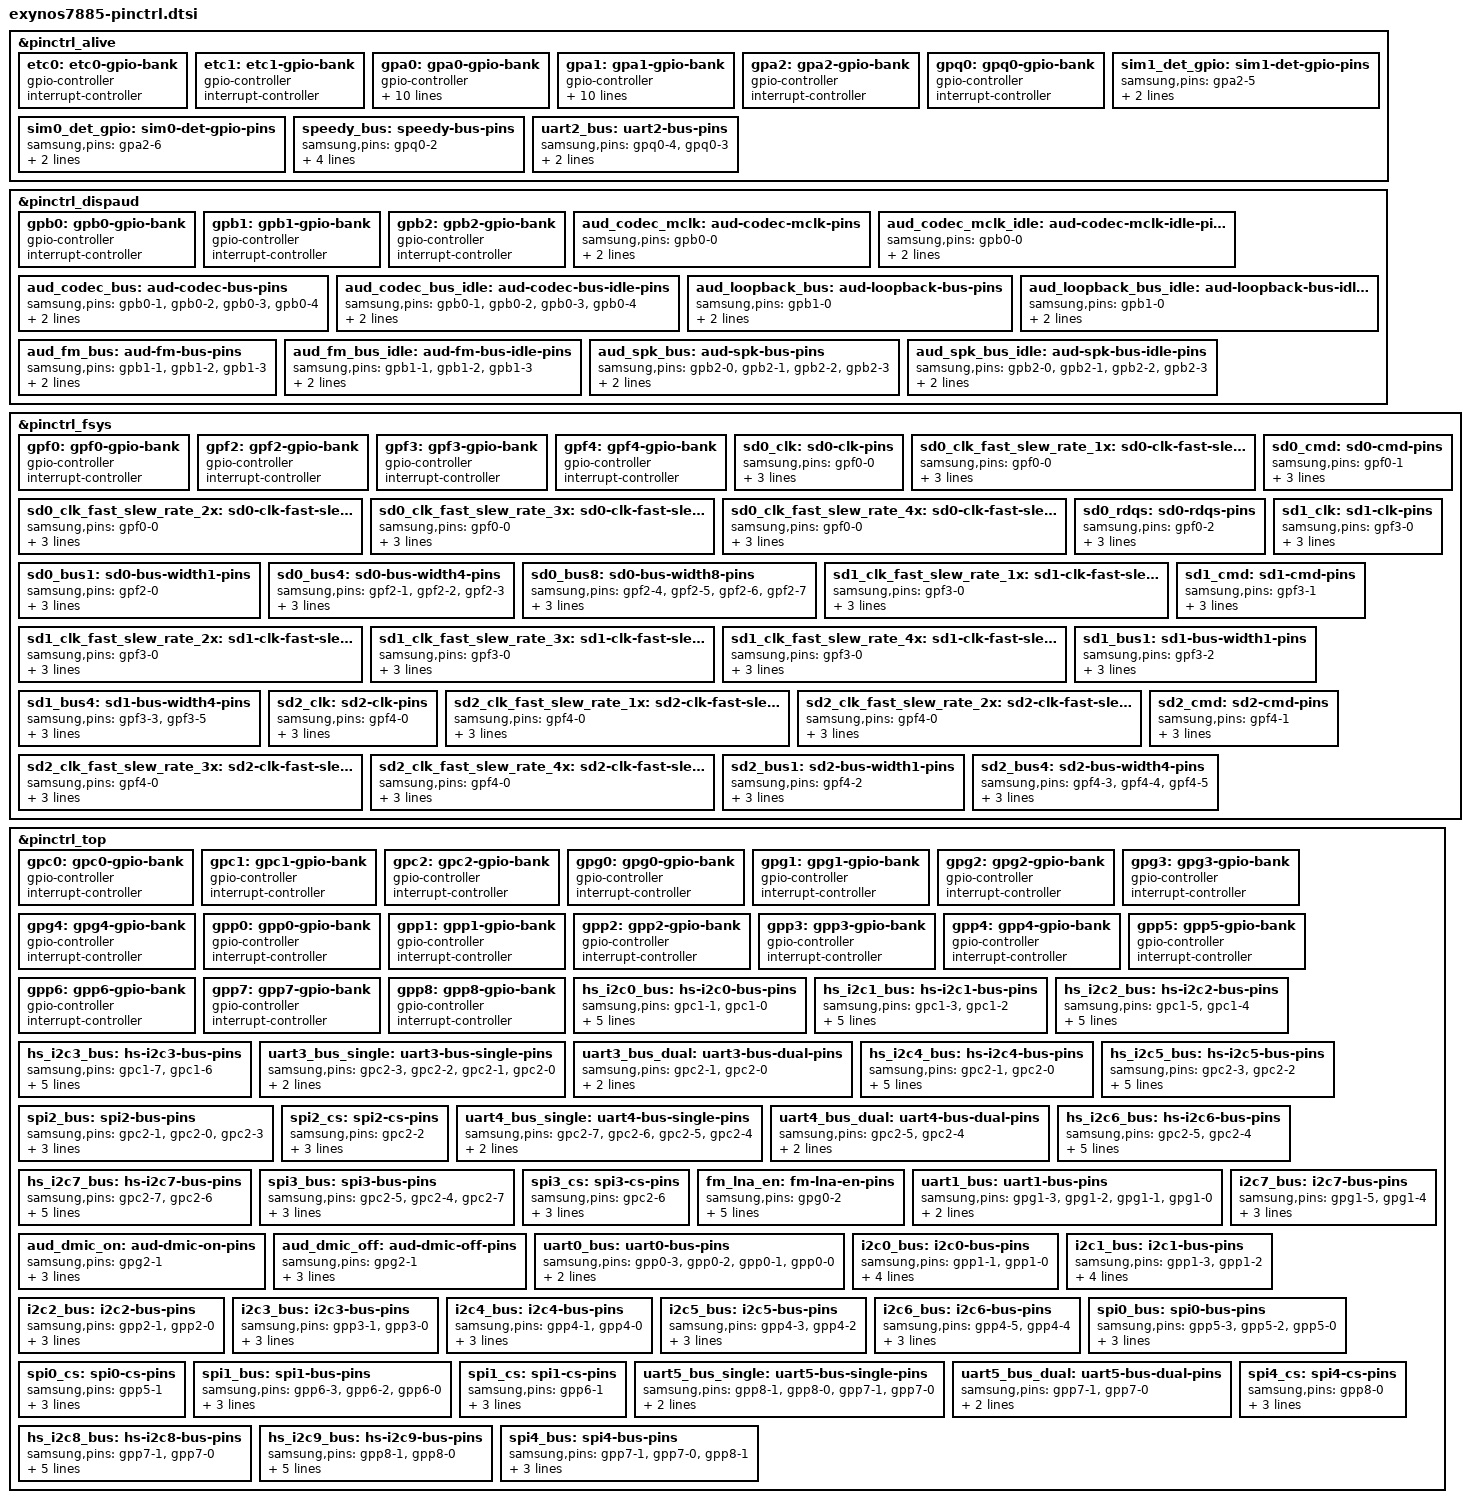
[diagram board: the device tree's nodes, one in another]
// SPDX-License-Identifier: GPL-2.0
/*
 * Samsung Exynos7885 SoC pin-mux and pin-config device tree source
 *
 * Copyright (c) 2017 Samsung Electronics Co., Ltd.
 * Copyright (c) 2021 Dávid Virág
 *
 * Samsung's Exynos7885 SoC pin-mux and pin-config options are listed as
 * device tree nodes in this file.
 */

#include <dt-bindings/pinctrl/samsung.h>
#include <dt-bindings/interrupt-controller/arm-gic.h>

&pinctrl_alive {
	etc0: etc0-gpio-bank {
		gpio-controller;
		#gpio-cells = <2>;

		interrupt-controller;
		#interrupt-cells = <2>;
	};

	etc1: etc1-gpio-bank {
		gpio-controller;
		#gpio-cells = <2>;

		interrupt-controller;
		#interrupt-cells = <2>;
	};

	gpa0: gpa0-gpio-bank {
		gpio-controller;
		#gpio-cells = <2>;

		interrupt-controller;
		#interrupt-cells = <2>;
		interrupt-parent = <&gic>;
		interrupts = <GIC_SPI 0 IRQ_TYPE_LEVEL_HIGH>,
			     <GIC_SPI 1 IRQ_TYPE_LEVEL_HIGH>,
			     <GIC_SPI 2 IRQ_TYPE_LEVEL_HIGH>,
			     <GIC_SPI 3 IRQ_TYPE_LEVEL_HIGH>,
			     <GIC_SPI 4 IRQ_TYPE_LEVEL_HIGH>,
			     <GIC_SPI 5 IRQ_TYPE_LEVEL_HIGH>,
			     <GIC_SPI 6 IRQ_TYPE_LEVEL_HIGH>,
			     <GIC_SPI 7 IRQ_TYPE_LEVEL_HIGH>;
	};

	gpa1: gpa1-gpio-bank {
		gpio-controller;
		#gpio-cells = <2>;

		interrupt-controller;
		#interrupt-cells = <2>;
		interrupt-parent = <&gic>;
		interrupts = <GIC_SPI 8 IRQ_TYPE_LEVEL_HIGH>,
			     <GIC_SPI 9 IRQ_TYPE_LEVEL_HIGH>,
			     <GIC_SPI 10 IRQ_TYPE_LEVEL_HIGH>,
			     <GIC_SPI 11 IRQ_TYPE_LEVEL_HIGH>,
			     <GIC_SPI 12 IRQ_TYPE_LEVEL_HIGH>,
			     <GIC_SPI 13 IRQ_TYPE_LEVEL_HIGH>,
			     <GIC_SPI 14 IRQ_TYPE_LEVEL_HIGH>,
			     <GIC_SPI 15 IRQ_TYPE_LEVEL_HIGH>;
	};

	gpa2: gpa2-gpio-bank {
		gpio-controller;
		#gpio-cells = <2>;

		interrupt-controller;
		#interrupt-cells = <2>;
	};

	gpq0: gpq0-gpio-bank {
		gpio-controller;
		#gpio-cells = <2>;

		interrupt-controller;
		#interrupt-cells = <2>;
	};

	sim1_det_gpio: sim1-det-gpio-pins {
		samsung,pins = "gpa2-5";
		samsung,pin-function = <EXYNOS_PIN_FUNC_F>;
		samsung,pin-pud = <EXYNOS_PIN_PULL_NONE>;
	};

	sim0_det_gpio: sim0-det-gpio-pins {
		samsung,pins = "gpa2-6";
		samsung,pin-function = <EXYNOS_PIN_FUNC_F>;
		samsung,pin-pud = <EXYNOS_PIN_PULL_NONE>;
	};

	speedy_bus: speedy-bus-pins {
		samsung,pins = "gpq0-2";
		samsung,pin-function = <EXYNOS_PIN_FUNC_2>;
		samsung,pin-con-pdn = <EXYNOS_PIN_PDN_PREV>;
		samsung,pin-pud = <EXYNOS_PIN_PULL_UP>;
		samsung,pin-drv = <EXYNOS5420_PIN_DRV_LV1>;
	};

	/* UART_DEBUG */
	uart2_bus: uart2-bus-pins {
		samsung,pins = "gpq0-4", "gpq0-3";
		samsung,pin-function = <EXYNOS_PIN_FUNC_2>;
		samsung,pin-pud = <EXYNOS_PIN_PULL_NONE>;
	};
};

&pinctrl_dispaud {
	gpb0: gpb0-gpio-bank {
		gpio-controller;
		#gpio-cells = <2>;

		interrupt-controller;
		#interrupt-cells = <2>;
	};

	gpb1: gpb1-gpio-bank {
		gpio-controller;
		#gpio-cells = <2>;

		interrupt-controller;
		#interrupt-cells = <2>;
	};

	gpb2: gpb2-gpio-bank {
		gpio-controller;
		#gpio-cells = <2>;

		interrupt-controller;
		#interrupt-cells = <2>;
	};

	aud_codec_mclk: aud-codec-mclk-pins {
		samsung,pins = "gpb0-0";
		samsung,pin-function = <EXYNOS_PIN_FUNC_2>;
		samsung,pin-pud = <EXYNOS_PIN_PULL_DOWN>;
	};

	aud_codec_mclk_idle: aud-codec-mclk-idle-pins {
		samsung,pins = "gpb0-0";
		samsung,pin-function = <EXYNOS_PIN_FUNC_INPUT>;
		samsung,pin-pud = <EXYNOS_PIN_PULL_DOWN>;
	};

	aud_codec_bus: aud-codec-bus-pins {
		samsung,pins = "gpb0-1", "gpb0-2", "gpb0-3", "gpb0-4";
		samsung,pin-function = <EXYNOS_PIN_FUNC_2>;
		samsung,pin-pud = <EXYNOS_PIN_PULL_DOWN>;
	};

	aud_codec_bus_idle: aud-codec-bus-idle-pins {
		samsung,pins = "gpb0-1", "gpb0-2", "gpb0-3", "gpb0-4";
		samsung,pin-function = <EXYNOS_PIN_FUNC_INPUT>;
		samsung,pin-pud = <EXYNOS_PIN_PULL_DOWN>;
	};

	aud_loopback_bus: aud-loopback-bus-pins {
		samsung,pins = "gpb1-0";
		samsung,pin-function = <EXYNOS_PIN_FUNC_2>;
		samsung,pin-pud = <EXYNOS_PIN_PULL_DOWN>;
	};

	aud_loopback_bus_idle: aud-loopback-bus-idle-pins {
		samsung,pins = "gpb1-0";
		samsung,pin-function = <EXYNOS_PIN_FUNC_INPUT>;
		samsung,pin-pud = <EXYNOS_PIN_PULL_DOWN>;
	};

	aud_fm_bus: aud-fm-bus-pins {
		samsung,pins = "gpb1-1", "gpb1-2", "gpb1-3";
		samsung,pin-function = <EXYNOS_PIN_FUNC_2>;
		samsung,pin-pud = <EXYNOS_PIN_PULL_DOWN>;
	};

	aud_fm_bus_idle: aud-fm-bus-idle-pins {
		samsung,pins = "gpb1-1", "gpb1-2", "gpb1-3";
		samsung,pin-function = <EXYNOS_PIN_FUNC_INPUT>;
		samsung,pin-pud = <EXYNOS_PIN_PULL_DOWN>;
	};

	aud_spk_bus: aud-spk-bus-pins {
		samsung,pins = "gpb2-0", "gpb2-1", "gpb2-2", "gpb2-3";
		samsung,pin-function = <EXYNOS_PIN_FUNC_2>;
		samsung,pin-pud = <EXYNOS_PIN_PULL_DOWN>;
	};

	aud_spk_bus_idle: aud-spk-bus-idle-pins {
		samsung,pins = "gpb2-0", "gpb2-1", "gpb2-2", "gpb2-3";
		samsung,pin-function = <EXYNOS_PIN_FUNC_INPUT>;
		samsung,pin-pud = <EXYNOS_PIN_PULL_DOWN>;
	};
};

&pinctrl_fsys {
	gpf0: gpf0-gpio-bank {
		gpio-controller;
		#gpio-cells = <2>;

		interrupt-controller;
		#interrupt-cells = <2>;
	};

	gpf2: gpf2-gpio-bank {
		gpio-controller;
		#gpio-cells = <2>;

		interrupt-controller;
		#interrupt-cells = <2>;
	};

	gpf3: gpf3-gpio-bank {
		gpio-controller;
		#gpio-cells = <2>;

		interrupt-controller;
		#interrupt-cells = <2>;
	};

	gpf4: gpf4-gpio-bank {
		gpio-controller;
		#gpio-cells = <2>;

		interrupt-controller;
		#interrupt-cells = <2>;
	};

	sd0_clk: sd0-clk-pins {
		samsung,pins = "gpf0-0";
		samsung,pin-function = <EXYNOS_PIN_FUNC_2>;
		samsung,pin-pud = <EXYNOS_PIN_PULL_NONE>;
		samsung,pin-drv = <EXYNOS5420_PIN_DRV_LV4>;
	};

	sd0_clk_fast_slew_rate_1x: sd0-clk-fast-slew-rate-1x-pins {
		samsung,pins = "gpf0-0";
		samsung,pin-function = <EXYNOS_PIN_FUNC_2>;
		samsung,pin-pud = <EXYNOS_PIN_PULL_NONE>;
		samsung,pin-drv = <EXYNOS5420_PIN_DRV_LV1>;
	};

	sd0_clk_fast_slew_rate_2x: sd0-clk-fast-slew-rate-2x-pins {
		samsung,pins = "gpf0-0";
		samsung,pin-function = <EXYNOS_PIN_FUNC_2>;
		samsung,pin-pud = <EXYNOS_PIN_PULL_NONE>;
		samsung,pin-drv = <EXYNOS5420_PIN_DRV_LV2>;
	};

	sd0_clk_fast_slew_rate_3x: sd0-clk-fast-slew-rate-3x-pins {
		samsung,pins = "gpf0-0";
		samsung,pin-function = <EXYNOS_PIN_FUNC_2>;
		samsung,pin-pud = <EXYNOS_PIN_PULL_NONE>;
		samsung,pin-drv = <EXYNOS5420_PIN_DRV_LV3>;
	};

	sd0_clk_fast_slew_rate_4x: sd0-clk-fast-slew-rate-4x-pins {
		samsung,pins = "gpf0-0";
		samsung,pin-function = <EXYNOS_PIN_FUNC_2>;
		samsung,pin-pud = <EXYNOS_PIN_PULL_NONE>;
		samsung,pin-drv = <EXYNOS5420_PIN_DRV_LV4>;
	};

	sd0_cmd: sd0-cmd-pins {
		samsung,pins = "gpf0-1";
		samsung,pin-function = <EXYNOS_PIN_FUNC_2>;
		samsung,pin-pud = <EXYNOS_PIN_PULL_UP>;
		samsung,pin-drv = <EXYNOS5420_PIN_DRV_LV4>;
	};

	sd0_rdqs: sd0-rdqs-pins {
		samsung,pins = "gpf0-2";
		samsung,pin-function = <EXYNOS_PIN_FUNC_2>;
		samsung,pin-pud = <EXYNOS_PIN_PULL_DOWN>;
		samsung,pin-drv = <EXYNOS5420_PIN_DRV_LV4>;
	};

	sd0_bus1: sd0-bus-width1-pins {
		samsung,pins = "gpf2-0";
		samsung,pin-function = <EXYNOS_PIN_FUNC_2>;
		samsung,pin-pud = <EXYNOS_PIN_PULL_UP>;
		samsung,pin-drv = <EXYNOS5420_PIN_DRV_LV4>;
	};

	sd0_bus4: sd0-bus-width4-pins {
		samsung,pins = "gpf2-1", "gpf2-2", "gpf2-3";
		samsung,pin-function = <EXYNOS_PIN_FUNC_2>;
		samsung,pin-pud = <EXYNOS_PIN_PULL_UP>;
		samsung,pin-drv = <EXYNOS5420_PIN_DRV_LV4>;
	};

	sd0_bus8: sd0-bus-width8-pins {
		samsung,pins = "gpf2-4", "gpf2-5", "gpf2-6", "gpf2-7";
		samsung,pin-function = <EXYNOS_PIN_FUNC_2>;
		samsung,pin-pud = <EXYNOS_PIN_PULL_UP>;
		samsung,pin-drv = <EXYNOS5420_PIN_DRV_LV4>;
	};

	sd1_clk: sd1-clk-pins {
		samsung,pins = "gpf3-0";
		samsung,pin-function = <EXYNOS_PIN_FUNC_2>;
		samsung,pin-pud = <EXYNOS_PIN_PULL_NONE>;
		samsung,pin-drv = <EXYNOS5420_PIN_DRV_LV3>;
	};

	sd1_clk_fast_slew_rate_1x: sd1-clk-fast-slew-rate-1x-pins {
		samsung,pins = "gpf3-0";
		samsung,pin-function = <EXYNOS_PIN_FUNC_2>;
		samsung,pin-pud = <EXYNOS_PIN_PULL_NONE>;
		samsung,pin-drv = <EXYNOS5420_PIN_DRV_LV1>;
	};

	sd1_clk_fast_slew_rate_2x: sd1-clk-fast-slew-rate-2x-pins {
		samsung,pins = "gpf3-0";
		samsung,pin-function = <EXYNOS_PIN_FUNC_2>;
		samsung,pin-pud = <EXYNOS_PIN_PULL_NONE>;
		samsung,pin-drv = <EXYNOS5420_PIN_DRV_LV2>;
	};

	sd1_clk_fast_slew_rate_3x: sd1-clk-fast-slew-rate-3x-pins {
		samsung,pins = "gpf3-0";
		samsung,pin-function = <EXYNOS_PIN_FUNC_2>;
		samsung,pin-pud = <EXYNOS_PIN_PULL_NONE>;
		samsung,pin-drv = <EXYNOS5420_PIN_DRV_LV3>;
	};

	sd1_clk_fast_slew_rate_4x: sd1-clk-fast-slew-rate-4x-pins {
		samsung,pins = "gpf3-0";
		samsung,pin-function = <EXYNOS_PIN_FUNC_2>;
		samsung,pin-pud = <EXYNOS_PIN_PULL_NONE>;
		samsung,pin-drv = <EXYNOS5420_PIN_DRV_LV4>;
	};

	sd1_cmd: sd1-cmd-pins {
		samsung,pins = "gpf3-1";
		samsung,pin-function = <EXYNOS_PIN_FUNC_2>;
		samsung,pin-pud = <EXYNOS_PIN_PULL_UP>;
		samsung,pin-drv = <EXYNOS5420_PIN_DRV_LV3>;
	};

	sd1_bus1: sd1-bus-width1-pins {
		samsung,pins = "gpf3-2";
		samsung,pin-function = <EXYNOS_PIN_FUNC_2>;
		samsung,pin-pud = <EXYNOS_PIN_PULL_UP>;
		samsung,pin-drv = <EXYNOS5420_PIN_DRV_LV3>;
	};

	sd1_bus4: sd1-bus-width4-pins {
		samsung,pins = "gpf3-3", "gpf3-5";
		samsung,pin-function = <EXYNOS_PIN_FUNC_2>;
		samsung,pin-pud = <EXYNOS_PIN_PULL_UP>;
		samsung,pin-drv = <EXYNOS5420_PIN_DRV_LV3>;
	};

	sd2_clk: sd2-clk-pins {
		samsung,pins = "gpf4-0";
		samsung,pin-function = <EXYNOS_PIN_FUNC_2>;
		samsung,pin-pud = <EXYNOS_PIN_PULL_NONE>;
		samsung,pin-drv = <EXYNOS5420_PIN_DRV_LV3>;
	};

	sd2_clk_fast_slew_rate_1x: sd2-clk-fast-slew-rate-1x-pins {
		samsung,pins = "gpf4-0";
		samsung,pin-function = <EXYNOS_PIN_FUNC_2>;
		samsung,pin-pud = <EXYNOS_PIN_PULL_NONE>;
		samsung,pin-drv = <EXYNOS5420_PIN_DRV_LV1>;
	};

	sd2_clk_fast_slew_rate_2x: sd2-clk-fast-slew-rate-2x-pins {
		samsung,pins = "gpf4-0";
		samsung,pin-function = <EXYNOS_PIN_FUNC_2>;
		samsung,pin-pud = <EXYNOS_PIN_PULL_NONE>;
		samsung,pin-drv = <EXYNOS5420_PIN_DRV_LV2>;
	};

	sd2_clk_fast_slew_rate_3x: sd2-clk-fast-slew-rate-3x-pins {
		samsung,pins = "gpf4-0";
		samsung,pin-function = <EXYNOS_PIN_FUNC_2>;
		samsung,pin-pud = <EXYNOS_PIN_PULL_NONE>;
		samsung,pin-drv = <EXYNOS5420_PIN_DRV_LV3>;
	};

	sd2_clk_fast_slew_rate_4x: sd2-clk-fast-slew-rate-4x-pins {
		samsung,pins = "gpf4-0";
		samsung,pin-function = <EXYNOS_PIN_FUNC_2>;
		samsung,pin-pud = <EXYNOS_PIN_PULL_NONE>;
		samsung,pin-drv = <EXYNOS5420_PIN_DRV_LV4>;
	};

	sd2_cmd: sd2-cmd-pins {
		samsung,pins = "gpf4-1";
		samsung,pin-function = <EXYNOS_PIN_FUNC_2>;
		samsung,pin-pud = <EXYNOS_PIN_PULL_UP>;
		samsung,pin-drv = <EXYNOS5420_PIN_DRV_LV3>;
	};

	sd2_bus1: sd2-bus-width1-pins {
		samsung,pins = "gpf4-2";
		samsung,pin-function = <EXYNOS_PIN_FUNC_2>;
		samsung,pin-pud = <EXYNOS_PIN_PULL_UP>;
		samsung,pin-drv = <EXYNOS5420_PIN_DRV_LV3>;
	};

	sd2_bus4: sd2-bus-width4-pins {
		samsung,pins = "gpf4-3", "gpf4-4", "gpf4-5";
		samsung,pin-function = <EXYNOS_PIN_FUNC_2>;
		samsung,pin-pud = <EXYNOS_PIN_PULL_UP>;
		samsung,pin-drv = <EXYNOS5420_PIN_DRV_LV3>;
	};
};

&pinctrl_top {
	gpc0: gpc0-gpio-bank {
		gpio-controller;
		#gpio-cells = <2>;

		interrupt-controller;
		#interrupt-cells = <2>;
	};

	gpc1: gpc1-gpio-bank {
		gpio-controller;
		#gpio-cells = <2>;

		interrupt-controller;
		#interrupt-cells = <2>;
	};

	gpc2: gpc2-gpio-bank {
		gpio-controller;
		#gpio-cells = <2>;

		interrupt-controller;
		#interrupt-cells = <2>;
	};

	gpg0: gpg0-gpio-bank {
		gpio-controller;
		#gpio-cells = <2>;

		interrupt-controller;
		#interrupt-cells = <2>;
	};

	gpg1: gpg1-gpio-bank {
		gpio-controller;
		#gpio-cells = <2>;

		interrupt-controller;
		#interrupt-cells = <2>;
	};

	gpg2: gpg2-gpio-bank {
		gpio-controller;
		#gpio-cells = <2>;

		interrupt-controller;
		#interrupt-cells = <2>;
	};

	gpg3: gpg3-gpio-bank {
		gpio-controller;
		#gpio-cells = <2>;

		interrupt-controller;
		#interrupt-cells = <2>;
	};

	gpg4: gpg4-gpio-bank {
		gpio-controller;
		#gpio-cells = <2>;

		interrupt-controller;
		#interrupt-cells = <2>;
	};

	gpp0: gpp0-gpio-bank {
		gpio-controller;
		#gpio-cells = <2>;

		interrupt-controller;
		#interrupt-cells = <2>;
	};

	gpp1: gpp1-gpio-bank {
		gpio-controller;
		#gpio-cells = <2>;

		interrupt-controller;
		#interrupt-cells = <2>;
	};

	gpp2: gpp2-gpio-bank {
		gpio-controller;
		#gpio-cells = <2>;

		interrupt-controller;
		#interrupt-cells = <2>;
	};

	gpp3: gpp3-gpio-bank {
		gpio-controller;
		#gpio-cells = <2>;

		interrupt-controller;
		#interrupt-cells = <2>;
	};

	gpp4: gpp4-gpio-bank {
		gpio-controller;
		#gpio-cells = <2>;

		interrupt-controller;
		#interrupt-cells = <2>;
	};

	gpp5: gpp5-gpio-bank {
		gpio-controller;
		#gpio-cells = <2>;

		interrupt-controller;
		#interrupt-cells = <2>;
	};

	gpp6: gpp6-gpio-bank {
		gpio-controller;
		#gpio-cells = <2>;

		interrupt-controller;
		#interrupt-cells = <2>;
	};

	gpp7: gpp7-gpio-bank {
		gpio-controller;
		#gpio-cells = <2>;

		interrupt-controller;
		#interrupt-cells = <2>;
	};

	gpp8: gpp8-gpio-bank {
		gpio-controller;
		#gpio-cells = <2>;

		interrupt-controller;
		#interrupt-cells = <2>;
	};

	hs_i2c0_bus: hs-i2c0-bus-pins {
		samsung,pins = "gpc1-1", "gpc1-0";
		samsung,pin-function = <EXYNOS_PIN_FUNC_2>;
		samsung,pin-con-pdn = <EXYNOS_PIN_PDN_OUT1>;
		samsung,pin-pud-pdn = <EXYNOS_PIN_PULL_UP>;
		samsung,pin-pud = <EXYNOS_PIN_PULL_NONE>;
		samsung,pin-drv = <EXYNOS5420_PIN_DRV_LV1>;
	};

	hs_i2c1_bus: hs-i2c1-bus-pins {
		samsung,pins = "gpc1-3", "gpc1-2";
		samsung,pin-function = <EXYNOS_PIN_FUNC_2>;
		samsung,pin-pud = <EXYNOS_PIN_PULL_NONE>;
		samsung,pin-drv = <EXYNOS5420_PIN_DRV_LV1>;
		samsung,pin-con-pdn = <EXYNOS_PIN_PDN_OUT1>;
		samsung,pin-pud-pdn = <EXYNOS_PIN_PULL_UP>;
	};

	hs_i2c2_bus: hs-i2c2-bus-pins {
		samsung,pins = "gpc1-5", "gpc1-4";
		samsung,pin-function = <EXYNOS_PIN_FUNC_2>;
		samsung,pin-pud = <EXYNOS_PIN_PULL_NONE>;
		samsung,pin-drv = <EXYNOS5420_PIN_DRV_LV1>;
		samsung,pin-con-pdn = <EXYNOS_PIN_PDN_OUT1>;
		samsung,pin-pud-pdn = <EXYNOS_PIN_PULL_UP>;
	};

	hs_i2c3_bus: hs-i2c3-bus-pins {
		samsung,pins = "gpc1-7", "gpc1-6";
		samsung,pin-function = <EXYNOS_PIN_FUNC_2>;
		samsung,pin-pud = <EXYNOS_PIN_PULL_NONE>;
		samsung,pin-drv = <EXYNOS5420_PIN_DRV_LV1>;
		samsung,pin-con-pdn = <EXYNOS_PIN_PDN_OUT1>;
		samsung,pin-pud-pdn = <EXYNOS_PIN_PULL_UP>;
	};

	/* USI0 UART */
	uart3_bus_single: uart3-bus-single-pins {
		samsung,pins = "gpc2-3", "gpc2-2", "gpc2-1", "gpc2-0";
		samsung,pin-function = <EXYNOS_PIN_FUNC_2>;
		samsung,pin-pud = <EXYNOS_PIN_PULL_NONE>;
	};

	/* USI0 UART_HSI2C1 */
	uart3_bus_dual: uart3-bus-dual-pins {
		samsung,pins = "gpc2-1", "gpc2-0";
		samsung,pin-function = <EXYNOS_PIN_FUNC_2>;
		samsung,pin-pud = <EXYNOS_PIN_PULL_NONE>;
	};

	/* USI0 HSI2C0 */
	hs_i2c4_bus: hs-i2c4-bus-pins {
		samsung,pins = "gpc2-1", "gpc2-0";
		samsung,pin-function = <EXYNOS_PIN_FUNC_2>;
		samsung,pin-pud = <EXYNOS_PIN_PULL_NONE>;
		samsung,pin-drv = <EXYNOS5420_PIN_DRV_LV1>;
		samsung,pin-con-pdn = <EXYNOS_PIN_PDN_OUT1>;
		samsung,pin-pud-pdn = <EXYNOS_PIN_PULL_UP>;
	};

	/* USI0 HSI2C1 */
	hs_i2c5_bus: hs-i2c5-bus-pins {
		samsung,pins = "gpc2-3", "gpc2-2";
		samsung,pin-function = <EXYNOS_PIN_FUNC_2>;
		samsung,pin-pud = <EXYNOS_PIN_PULL_NONE>;
		samsung,pin-drv = <EXYNOS5420_PIN_DRV_LV1>;
		samsung,pin-con-pdn = <EXYNOS_PIN_PDN_OUT1>;
		samsung,pin-pud-pdn = <EXYNOS_PIN_PULL_UP>;
	};

	/* USI0 SPI */
	spi2_bus: spi2-bus-pins {
		samsung,pins = "gpc2-1", "gpc2-0", "gpc2-3";
		samsung,pin-function = <EXYNOS_PIN_FUNC_2>;
		samsung,pin-pud = <EXYNOS_PIN_PULL_UP>;
		samsung,pin-drv = <EXYNOS5420_PIN_DRV_LV1>;
	};

	spi2_cs: spi2-cs-pins {
		samsung,pins = "gpc2-2";
		samsung,pin-function = <EXYNOS_PIN_FUNC_OUTPUT>;
		samsung,pin-pud = <EXYNOS_PIN_PULL_UP>;
		samsung,pin-drv = <EXYNOS5420_PIN_DRV_LV1>;
	};

	/* USI1 UART */
	uart4_bus_single: uart4-bus-single-pins {
		samsung,pins = "gpc2-7", "gpc2-6", "gpc2-5", "gpc2-4";
		samsung,pin-function = <EXYNOS_PIN_FUNC_2>;
		samsung,pin-pud = <EXYNOS_PIN_PULL_NONE>;
	};

	/* USI1 UART_HSI2C1*/
	uart4_bus_dual: uart4-bus-dual-pins {
		samsung,pins = "gpc2-5", "gpc2-4";
		samsung,pin-function = <EXYNOS_PIN_FUNC_2>;
		samsung,pin-pud = <EXYNOS_PIN_PULL_NONE>;
	};

	/* USI1 HSI2C0 */
	hs_i2c6_bus: hs-i2c6-bus-pins {
		samsung,pins = "gpc2-5", "gpc2-4";
		samsung,pin-function = <EXYNOS_PIN_FUNC_2>;
		samsung,pin-pud = <EXYNOS_PIN_PULL_NONE>;
		samsung,pin-drv = <EXYNOS5420_PIN_DRV_LV1>;
		samsung,pin-con-pdn = <EXYNOS_PIN_PDN_OUT1>;
		samsung,pin-pud-pdn = <EXYNOS_PIN_PULL_UP>;
	};

	/* USI1 HSI2C1 */
	hs_i2c7_bus: hs-i2c7-bus-pins {
		samsung,pins = "gpc2-7", "gpc2-6";
		samsung,pin-function = <EXYNOS_PIN_FUNC_2>;
		samsung,pin-pud = <EXYNOS_PIN_PULL_NONE>;
		samsung,pin-drv = <EXYNOS5420_PIN_DRV_LV1>;
		samsung,pin-con-pdn = <EXYNOS_PIN_PDN_OUT1>;
		samsung,pin-pud-pdn = <EXYNOS_PIN_PULL_UP>;
	};

	/* USI1 SPI */
	spi3_bus: spi3-bus-pins {
		samsung,pins = "gpc2-5", "gpc2-4", "gpc2-7";
		samsung,pin-function = <EXYNOS_PIN_FUNC_2>;
		samsung,pin-pud = <EXYNOS_PIN_PULL_UP>;
		samsung,pin-drv = <EXYNOS5420_PIN_DRV_LV1>;
	};

	spi3_cs: spi3-cs-pins {
		samsung,pins = "gpc2-6";
		samsung,pin-function = <EXYNOS_PIN_FUNC_OUTPUT>;
		samsung,pin-pud = <EXYNOS_PIN_PULL_UP>;
		samsung,pin-drv = <EXYNOS5420_PIN_DRV_LV1>;
	};

	fm_lna_en: fm-lna-en-pins {
		samsung,pins = "gpg0-2";
		samsung,pin-function = <EXYNOS_PIN_FUNC_OUTPUT>;
		samsung,pin-pud = <EXYNOS_PIN_PULL_DOWN>;
		samsung,pin-con-pdn = <EXYNOS_PIN_PDN_PREV>;
		samsung,pin-pud-pdn = <EXYNOS_PIN_PULL_UP>;
		samsung,pin-val = <1>;
	};

	uart1_bus: uart1-bus-pins {
		samsung,pins = "gpg1-3", "gpg1-2", "gpg1-1", "gpg1-0";
		samsung,pin-function = <EXYNOS_PIN_FUNC_2>;
		samsung,pin-pud = <EXYNOS_PIN_PULL_NONE>;
	};

	i2c7_bus: i2c7-bus-pins {
		samsung,pins = "gpg1-5", "gpg1-4";
		samsung,pin-function = <EXYNOS_PIN_FUNC_2>;
		samsung,pin-pud = <EXYNOS_PIN_PULL_UP>;
		samsung,pin-drv = <EXYNOS5420_PIN_DRV_LV1>;
	};

	aud_dmic_on: aud-dmic-on-pins {
		samsung,pins = "gpg2-1";
		samsung,pin-function = <EXYNOS_PIN_FUNC_OUTPUT>;
		samsung,pin-con-pdn = <EXYNOS_PIN_PDN_PREV>;
		samsung,pin-val = <1>;
	};

	aud_dmic_off: aud-dmic-off-pins {
		samsung,pins = "gpg2-1";
		samsung,pin-function = <EXYNOS_PIN_FUNC_OUTPUT>;
		samsung,pin-con-pdn = <EXYNOS_PIN_PDN_PREV>;
		samsung,pin-val = <0>;
	};

	/* UART_HEALTH */
	uart0_bus: uart0-bus-pins {
		samsung,pins = "gpp0-3", "gpp0-2", "gpp0-1", "gpp0-0";
		samsung,pin-function = <EXYNOS_PIN_FUNC_2>;
		samsung,pin-pud = <EXYNOS_PIN_PULL_NONE>;
	};

	i2c0_bus: i2c0-bus-pins {
		samsung,pins = "gpp1-1", "gpp1-0";
		samsung,pin-function = <EXYNOS_PIN_FUNC_2>;
		samsung,pin-con-pdn = <EXYNOS_PIN_PDN_PREV>;
		samsung,pin-pud = <EXYNOS_PIN_PULL_UP>;
		samsung,pin-drv = <EXYNOS5420_PIN_DRV_LV1>;
	};

	i2c1_bus: i2c1-bus-pins {
		samsung,pins = "gpp1-3", "gpp1-2";
		samsung,pin-function = <EXYNOS_PIN_FUNC_2>;
		samsung,pin-con-pdn = <EXYNOS_PIN_PDN_PREV>;
		samsung,pin-pud = <EXYNOS_PIN_PULL_UP>;
		samsung,pin-drv = <EXYNOS5420_PIN_DRV_LV1>;
	};

	i2c2_bus: i2c2-bus-pins {
		samsung,pins = "gpp2-1", "gpp2-0";
		samsung,pin-function = <EXYNOS_PIN_FUNC_2>;
		samsung,pin-pud = <EXYNOS_PIN_PULL_UP>;
		samsung,pin-drv = <EXYNOS5420_PIN_DRV_LV1>;
	};

	i2c3_bus: i2c3-bus-pins {
		samsung,pins = "gpp3-1", "gpp3-0";
		samsung,pin-function = <EXYNOS_PIN_FUNC_2>;
		samsung,pin-pud = <EXYNOS_PIN_PULL_UP>;
		samsung,pin-drv = <EXYNOS5420_PIN_DRV_LV1>;
	};

	i2c4_bus: i2c4-bus-pins {
		samsung,pins = "gpp4-1", "gpp4-0";
		samsung,pin-function = <EXYNOS_PIN_FUNC_2>;
		samsung,pin-pud = <EXYNOS_PIN_PULL_UP>;
		samsung,pin-drv = <EXYNOS5420_PIN_DRV_LV1>;
	};

	i2c5_bus: i2c5-bus-pins {
		samsung,pins = "gpp4-3", "gpp4-2";
		samsung,pin-function = <EXYNOS_PIN_FUNC_2>;
		samsung,pin-pud = <EXYNOS_PIN_PULL_UP>;
		samsung,pin-drv = <EXYNOS5420_PIN_DRV_LV1>;
	};

	i2c6_bus: i2c6-bus-pins {
		samsung,pins = "gpp4-5", "gpp4-4";
		samsung,pin-function = <EXYNOS_PIN_FUNC_2>;
		samsung,pin-pud = <EXYNOS_PIN_PULL_UP>;
		samsung,pin-drv = <EXYNOS5420_PIN_DRV_LV1>;
	};

	/* SPI_ESE */
	spi0_bus: spi0-bus-pins {
		samsung,pins = "gpp5-3", "gpp5-2", "gpp5-0";
		samsung,pin-function = <EXYNOS_PIN_FUNC_2>;
		samsung,pin-pud = <EXYNOS_PIN_PULL_UP>;
		samsung,pin-drv = <EXYNOS5420_PIN_DRV_LV1>;
	};

	spi0_cs: spi0-cs-pins {
		samsung,pins = "gpp5-1";
		samsung,pin-function = <EXYNOS_PIN_FUNC_OUTPUT>;
		samsung,pin-pud = <EXYNOS_PIN_PULL_UP>;
		samsung,pin-drv = <EXYNOS5420_PIN_DRV_LV1>;
	};

	/* SPI_FP */
	spi1_bus: spi1-bus-pins {
		samsung,pins = "gpp6-3", "gpp6-2", "gpp6-0";
		samsung,pin-function = <EXYNOS_PIN_FUNC_2>;
		samsung,pin-pud = <EXYNOS_PIN_PULL_UP>;
		samsung,pin-drv = <EXYNOS5420_PIN_DRV_LV1>;
	};

	spi1_cs: spi1-cs-pins {
		samsung,pins = "gpp6-1";
		samsung,pin-function = <EXYNOS_PIN_FUNC_OUTPUT>;
		samsung,pin-pud = <EXYNOS_PIN_PULL_UP>;
		samsung,pin-drv = <EXYNOS5420_PIN_DRV_LV1>;
	};

	/* USI2 UART */
	uart5_bus_single: uart5-bus-single-pins {
		samsung,pins = "gpp8-1", "gpp8-0", "gpp7-1", "gpp7-0";
		samsung,pin-function = <EXYNOS_PIN_FUNC_2>;
		samsung,pin-pud = <EXYNOS_PIN_PULL_NONE>;
	  };

	/* USI2 UART_HSI2C1 */
	uart5_bus_dual: uart5-bus-dual-pins {
		samsung,pins = "gpp7-1", "gpp7-0";
		samsung,pin-function = <EXYNOS_PIN_FUNC_2>;
		samsung,pin-pud = <EXYNOS_PIN_PULL_NONE>;
	};

	/* USI2 HSI2C0 */
	hs_i2c8_bus: hs-i2c8-bus-pins {
		samsung,pins = "gpp7-1", "gpp7-0";
		samsung,pin-function = <EXYNOS_PIN_FUNC_2>;
		samsung,pin-pud = <EXYNOS_PIN_PULL_NONE>;
		samsung,pin-drv = <EXYNOS5420_PIN_DRV_LV1>;
		samsung,pin-con-pdn = <EXYNOS_PIN_PDN_OUT1>;
		samsung,pin-pud-pdn = <EXYNOS_PIN_PULL_UP>;
	};

	/* USI2 HSI2C1 */
	hs_i2c9_bus: hs-i2c9-bus-pins {
		samsung,pins = "gpp8-1", "gpp8-0";
		samsung,pin-function = <EXYNOS_PIN_FUNC_2>;
		samsung,pin-pud = <EXYNOS_PIN_PULL_NONE>;
		samsung,pin-drv = <EXYNOS5420_PIN_DRV_LV1>;
		samsung,pin-con-pdn = <EXYNOS_PIN_PDN_OUT1>;
		samsung,pin-pud-pdn = <EXYNOS_PIN_PULL_UP>;
	};

	/* USI2 SPI */
	spi4_bus: spi4-bus-pins {
		samsung,pins = "gpp7-1", "gpp7-0", "gpp8-1";
		samsung,pin-function = <EXYNOS_PIN_FUNC_2>;
		samsung,pin-pud = <EXYNOS_PIN_PULL_UP>;
		samsung,pin-drv = <EXYNOS5420_PIN_DRV_LV1>;
	};

	spi4_cs: spi4-cs-pins {
		samsung,pins = "gpp8-0";
		samsung,pin-function = <EXYNOS_PIN_FUNC_OUTPUT>;
		samsung,pin-pud = <EXYNOS_PIN_PULL_UP>;
		samsung,pin-drv = <EXYNOS5420_PIN_DRV_LV1>;
	};
};
